# ARMv8M-Baseline register map
Registers are read-only, no defined reset value unless marked. A register's access mark holds for its fields unless they carry their own. Offsets are from the block's base; [hi:lo] are bit positions; {n}, {i} and the like mark numbered series; 'fields as' and 'values as' point back to an identical list.

## MPU — Memory Protection Unit
Base 0xE000ED90
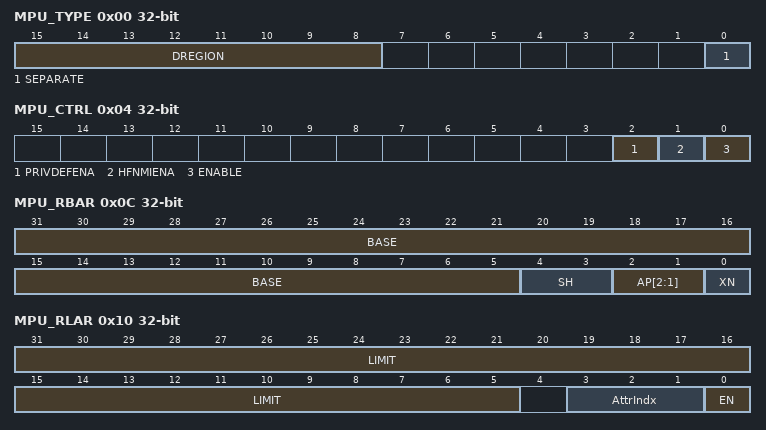
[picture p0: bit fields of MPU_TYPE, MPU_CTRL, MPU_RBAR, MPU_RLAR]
0x00 MPU_TYPE — MPU Type Register the MPU Type Register indicates how many regions the MPU for the selected Security state supports
  [15:8] DREGION — Data regions. Number of regions supported by the MPU
  [0] SEPARATE — Separate. Indicates support for separate instructions and data address regions
0x04 MPU_CTRL rw — MPU Control Register enables the MPU and, when the MPU is enabled, controls whether the default memory map is enabled as a background region for privileged accesses, and whether the MPU is enabled for HardFaults, NM
  [2] PRIVDEFENA — Privileged default enable
    0=Use of default memory map disabled; 1=Use of default memory map enabled for privilege code
  [1] HFNMIENA — HardFault, NMI enable
    0=MPU disabled for these handlers; 1=MPU enabled for these handlers
  [0] ENABLE — Enable. Enables the MPU
    0=The MPU is disabled; 1=The MPU is enabled
0x08 MPU_RNR rw — MPU Region Number Register selects the region currently accessed by MPU_RBAR and MPU_RLAR
  [7:0] REGION — Region number. Indicates the memory region accessed by MPU_RBAR and MPU_RLAR
0x0C MPU_RBAR rw — MPU Region Base Address Register provides indirect read and write access to the base address of the currently selected MPU region for the selected Security state
  [31:5] BASE — Base address. Contains bits [31:5] of the lower inclusive limit of the selected MPU memory region
  [4:3] SH — Shareability. Defines the Shareability domain of this region for Normal memory
    0=Non-shareable; 2=Outer Shareable; 3=Inner Shareable
  [2:1] AP[2:1] — Access permissions. Defines the access permissions for this region
    0=Read/write by privileged code only; 1=Read/write by any privilege level; 2=Read-only by privileged code only; 3=Read-only by any privilege level
  [0] XN — Execute Never. Defines whether code can be executed from this region
    0=Execution only permitted if read permitted; 1=Execution not permitted
0x10 MPU_RLAR rw — MPU Region Limit Address Register provides indirect read and write access to the limit address of the currently selected MPU region for the selected Security state
  [31:5] LIMIT — Limit address. Contains bits [31:5] of the upper inclusive limit of the selected MPU memory region
  [3:1] AttrIndx — Attribute index. Associates a set of attributes in the MPU_MAIR0 and MPU_MAIR1 fields
  [0] EN — Enable. Region enable
    0=Region disabled; 1=Region enabled
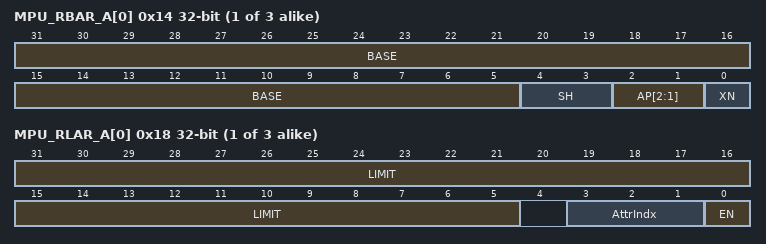
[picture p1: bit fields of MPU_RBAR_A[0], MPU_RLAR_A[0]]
{0x14+8i} MPU_RBAR_A[{i}] (i=0..2) rw — MPU Region Base Address Register Alias provides indirect read and write access to the base address of the MPU region selected by MPU_RNR[7:2]:(n[1:0]) for the selected Security state
  [31:5] BASE — Base address. Contains bits [31:5] of the lower inclusive limit of the selected MPU memory region
  [4:3] SH — Shareability. Defines the Shareability domain of this region for Normal memory
    0=Non-shareable; 2=Outer Shareable; 3=Inner Shareable
  [2:1] AP[2:1] — Access permissions. Defines the access permissions for this region
    0=Read/write by privileged code only; 1=Read/write by any privilege level; 2=Read-only by privileged code only
  [0] XN — Execute Never. Defines whether code can be executed from this region
    values as MPU_RBAR.XN
{0x18+8i} MPU_RLAR_A[{i}] (i=0..2) rw — MPU Region Limit Address Register Alias provides indirect read and write access to the limit address of the currently selected MPU region selected by MPU_RNR[7:2]:(n[1:0]) for the selected Security state
  fields as MPU_RLAR
0x30 MPU_MAIR0 rw — MPU Memory Attribute Indirection Register 0 along with MPU_MAIR1, provides the memory attribute encodings corresponding to the AttrIndx values
  [0] Attrm — Attribute m. Memory attribute encoding for MPU regions with an AttrIndx of m
0x34 MPU_MAIR1 rw — MPU Memory Attribute Indirection Register 1 along with MPU_MAIR0, provides the memory attribute encodings corresponding to the AttrIndx values
  fields as MPU_MAIR0
